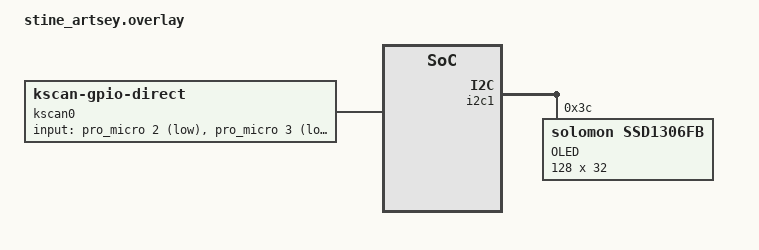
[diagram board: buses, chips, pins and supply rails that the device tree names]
&i2c1 {
    status = "okay";

    oled: oled@3c {
		compatible = "solomon,ssd1306fb";
		reg = <0x3c>;
		label = "OLED";
		width = <128>;
		height = <32>;
		segment-offset = <0>;
		page-offset = <0>;
		display-offset = <0>;
		multiplex-ratio = <31>;
		com-invdir;
		com-sequential;
		prechargep = <0x22>;
		inversion-on;
    };
};

/ {
    chosen {
		zmk,kscan = &kscan0;
		zephyr,display = &oled;
    };

    kscan0: kscan_0 {
	compatible = "zmk,kscan-gpio-direct";

	input-gpios
	    = <&pro_micro 2 (GPIO_ACTIVE_LOW | GPIO_PULL_UP)>
	    , <&pro_micro 3 (GPIO_ACTIVE_LOW | GPIO_PULL_UP)>
	    , <&pro_micro 4 (GPIO_ACTIVE_LOW | GPIO_PULL_UP)>
	    , <&pro_micro 5 (GPIO_ACTIVE_LOW | GPIO_PULL_UP)>
	    , <&pro_micro 6 (GPIO_ACTIVE_LOW | GPIO_PULL_UP)>
	    , <&pro_micro 7 (GPIO_ACTIVE_LOW | GPIO_PULL_UP)>
	    , <&pro_micro 8 (GPIO_ACTIVE_LOW | GPIO_PULL_UP)>
	    , <&pro_micro 9 (GPIO_ACTIVE_LOW | GPIO_PULL_UP)>
	    ;
    };
};
